VERSION ""

NS_ :

BS_:

BU_:

BO_ 3221225472 VECTOR__INDEPENDENT_SIG_MSG: 0 Vector__XXX
 SG_ Brake_Now : 0|8@1+ (1,0) [0|0] "" Vector__XXX

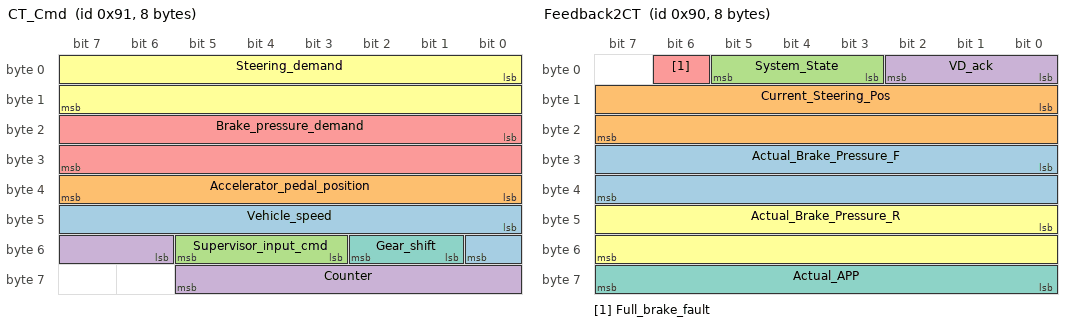
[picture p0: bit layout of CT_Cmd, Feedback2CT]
BO_ 145 CT_Cmd: 8 Vector__XXX
 SG_ Vehicle_speed : 40|9@1+ (1,0) [0|400] "" Vector__XXX
 SG_ Accelerator_pedal_position : 32|8@1+ (0.5,0) [0|100] "" Vector__XXX
 SG_ Supervisor_input_cmd : 51|3@1+ (1,0) [0|7] "" Vector__XXX
 SG_ Counter : 54|8@1+ (1,0) [0|255] "" Vector__XXX
 SG_ Brake_pressure_demand : 16|16@1+ (6894,0) [0|2068200] "" Vector__XXX
 SG_ Steering_demand : 0|16@1+ (0.1,-275) [-275|275] "" Vector__XXX
 SG_ Gear_shift : 49|2@1+ (1,0) [0|0] "" Vector__XXX

BO_ 144 Feedback2CT: 8 Vector__XXX
 SG_ Actual_Brake_Pressure_F : 24|16@1+ (6894,0) [0|2757600] "" Vector__XXX
 SG_ Current_Steering_Pos : 8|16@1+ (0.1,-275) [-275|275] "" Vector__XXX
 SG_ System_State : 3|3@1+ (1,0) [0|7] "" Vector__XXX
 SG_ VD_ack : 0|3@1+ (1,0) [0|7] "" Vector__XXX
 SG_ Full_brake_fault : 6|1@1+ (1,0) [0|255] "" Vector__XXX
 SG_ Actual_Brake_Pressure_R : 40|16@1+ (6894,0) [0|2757600] "" Vector__XXX
 SG_ Actual_APP : 56|8@1+ (1,0) [0|100] "" Vector__XXX

CM_ BO_ 3221225472 "This is a message for not used signals, created by Vector CANdb++ DBC OLE DB Provider.";
BA_DEF_  "BusType" STRING ;
BA_DEF_DEF_  "BusType" "";
BA_ "BusType" "CAN";
